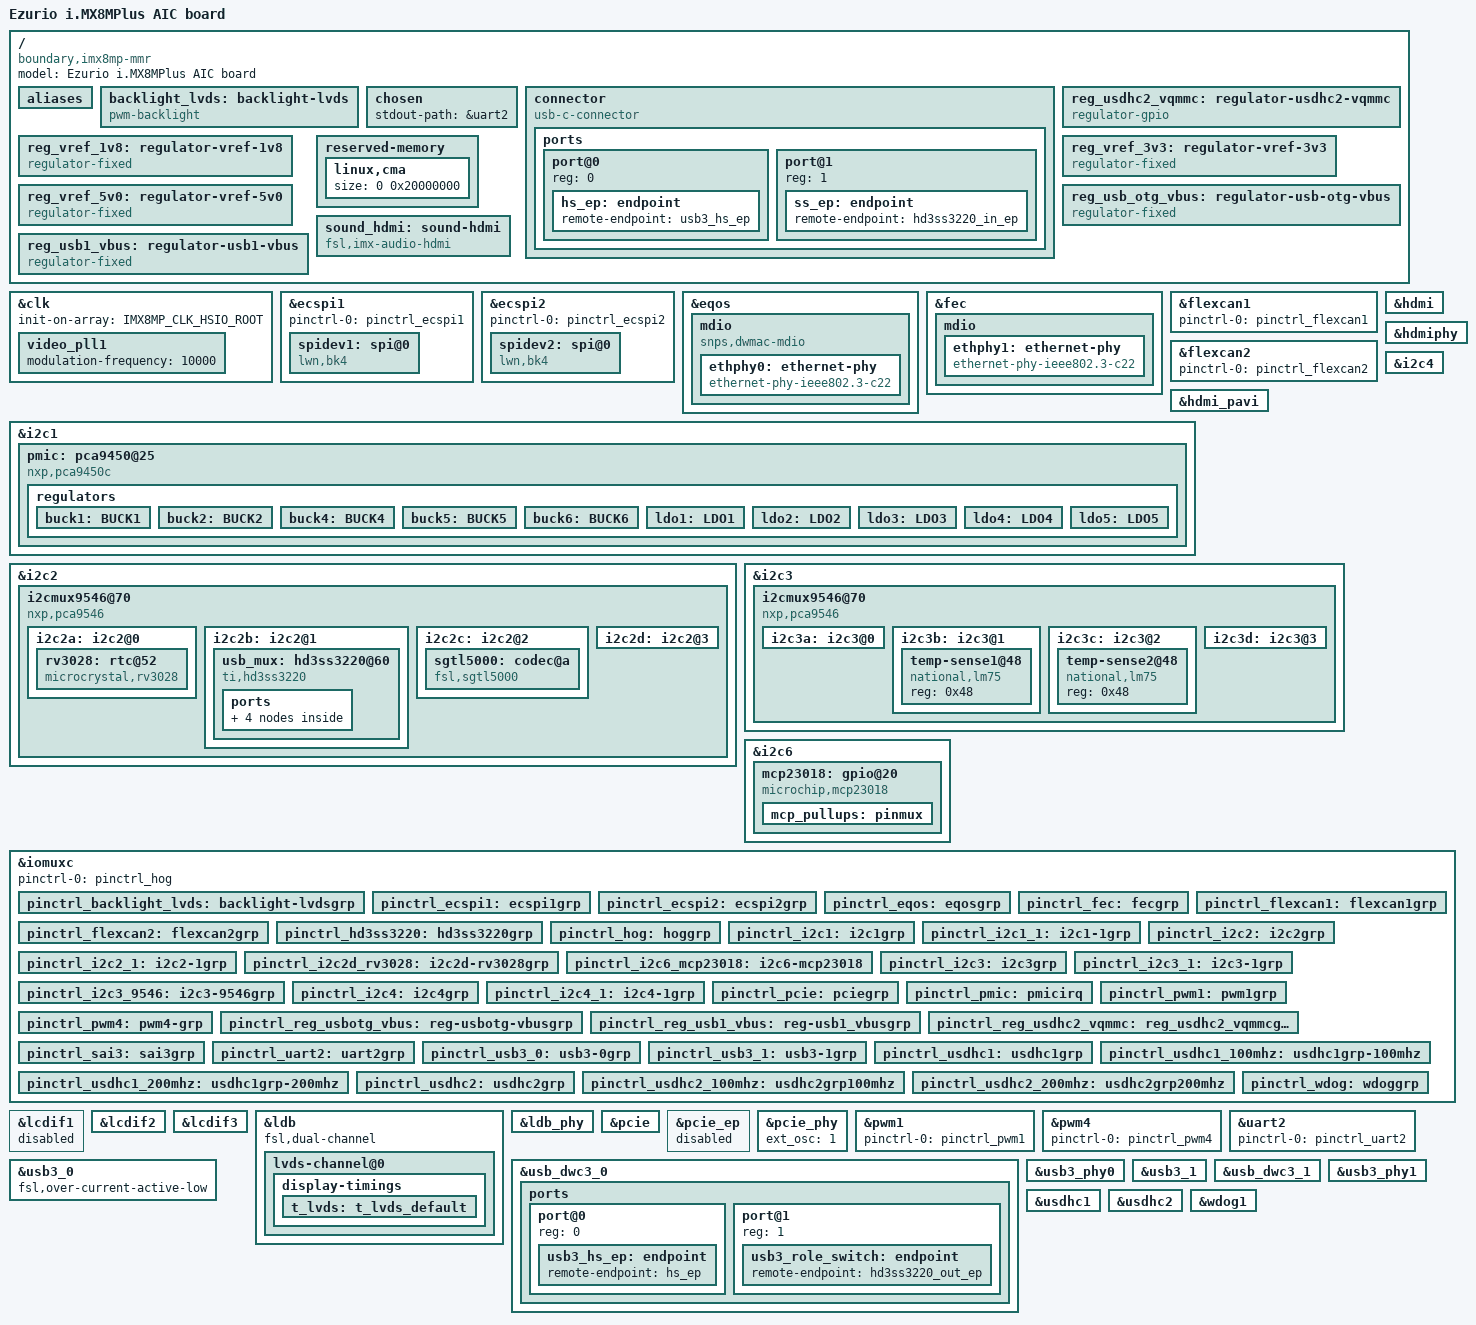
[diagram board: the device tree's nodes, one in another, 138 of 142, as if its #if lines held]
// SPDX-License-Identifier: (GPL-2.0+ OR MIT)
/*
 * Copyright 2020 Boundary Devices
 */

/dts-v1/;
#ifdef CONFIG_DEFCONFIG
#define UBOOT
#endif
#define IMX8MP

#include <dt-bindings/usb/pd.h>
#include "imx8mp.dtsi"
#include <dt-bindings/net/ti-dp83867.h>

/ {
	model = "Ezurio i.MX8MPlus AIC board";
	compatible = "boundary,imx8mp-mmr", "fsl,imx8mp";

	aliases {
		backlight_lvds = &backlight_lvds;
		ethernet0 = &eqos;
		ethernet1 = &fec;
		fb_lvds = &lcdif2;
		fb_lvds2 = &lcdif2;
		fb_hdmi = &lcdif3;
		lcdif = &lcdif1;
		ldb = &ldb;
		ldb_chan = &ldb_chan;
		ldb_chan2 = &ldb_chan2;
		pcie-phy = &pcie_phy;
		pwm_lvds = &pwm1;
		rtc0 = &rv3028;
		rtc1 = &snvs_rtc;
		sound_hdmi = &sound_hdmi;
		t_lvds = &t_lvds;
	};

	backlight_lvds: backlight-lvds {
		brightness-levels = <0 1 2 3 4 5 6 7 8 9 10>;
		compatible = "pwm-backlight";
		default-brightness-level = <8>;
		//enable-gpios = <&gpio4 3 GPIO_ACTIVE_HIGH>;
		//pinctrl-names = "default";
		//pinctrl-0 = <&pinctrl_backlight_lvds>;
		pwms = <&pwm1 0 100000 0>;
		status = "okay";
	};

	chosen {
		stdout-path = &uart2;
	};

	connector {
		compatible = "usb-c-connector";
		label = "USB-C";
		data-role = "dual";

		ports {
			#address-cells = <1>;
			#size-cells = <0>;

			port@0 {
				reg = <0>;
				hs_ep: endpoint {
					remote-endpoint = <&usb3_hs_ep>;
				};
			};

			port@1 {
				reg = <1>;
				ss_ep: endpoint {
					remote-endpoint = <&hd3ss3220_in_ep>;
				};
			};
		};
	};

	reg_usdhc2_vqmmc: regulator-usdhc2-vqmmc {
		compatible = "regulator-gpio";
		pinctrl-names = "default";
		pinctrl-0 = <&pinctrl_reg_usdhc2_vqmmc>;
		regulator-name = "reg_sd2_vsel";
		regulator-min-microvolt = <1800000>;
		regulator-max-microvolt = <3300000>;
		regulator-type = "voltage";
		regulator-boot-on;
		regulator-always-on;
		gpios = <&gpio1 4 GPIO_ACTIVE_HIGH>;
		states = <1800000 0x1
			  3300000 0x0>;
	};

	reg_vref_1v8: regulator-vref-1v8 {
		compatible = "regulator-fixed";
		regulator-name = "vref-1v8";
		regulator-min-microvolt = <1800000>;
		regulator-max-microvolt = <1800000>;
	};

	reg_vref_3v3: regulator-vref-3v3 {
		compatible = "regulator-fixed";
		regulator-name = "vref-3v3";
		regulator-min-microvolt = <3300000>;
		regulator-max-microvolt = <3300000>;
	};

	reg_vref_5v0: regulator-vref-5v0 {
		compatible = "regulator-fixed";
		regulator-name = "vref-5v0";
		regulator-min-microvolt = <5000000>;
		regulator-max-microvolt = <5000000>;
	};

	reg_usb_otg_vbus: regulator-usb-otg-vbus {
		compatible = "regulator-fixed";
		pinctrl-names = "default";
		pinctrl-0 = <&pinctrl_reg_usbotg_vbus>;
		regulator-name = "usb_otg_vbus";
		regulator-min-microvolt = <5000000>;
		regulator-max-microvolt = <5000000>;
		gpio = <&gpio1 13 GPIO_ACTIVE_HIGH>;
		enable-active-high;
	};

	reg_usb1_vbus: regulator-usb1-vbus {
		compatible = "regulator-fixed";
		pinctrl-names = "default";
		pinctrl-0 = <&pinctrl_reg_usb1_vbus>;
		regulator-name = "usb_host_vbus";
		regulator-min-microvolt = <5000000>;
		regulator-max-microvolt = <5000000>;
		gpio = <&gpio3 6 GPIO_ACTIVE_HIGH>;
		enable-active-high;
	};

	reserved-memory {
		linux,cma {
			size = <0 0x20000000>;
		};
	};

#ifndef UBOOT
	clk_pwm4: clock-pwm4 {
		compatible = "pwm-clock";
		#clock-cells = <0>;
		clock-frequency = <12000000>;
		clock-output-names = "codec-pwm4";
		pwms = <&pwm4 0 83 0>;
	};

	sound {
		compatible = "simple-audio-card";
		simple-audio-card,name = "SGTL5000-Card";
		simple-audio-card,format = "i2s";
		simple-audio-card,bitclock-master = <&codec_dai>;
		simple-audio-card,frame-master = <&codec_dai>;
		simple-audio-card,widgets = "Headphone", "Headphone Jack";
		simple-audio-card,routing = "Headphone Jack", "HP_OUT";

		cpu_dai: simple-audio-card,cpu {
			sound-dai = <&sai3>;
		};

		codec_dai: simple-audio-card,codec {
			sound-dai = <&sgtl5000>;
		};
	};
#endif
	sound_hdmi: sound-hdmi {
		compatible = "fsl,imx-audio-hdmi";
		model = "audio-hdmi";
#ifndef UBOOT
		audio-cpu = <&aud2htx>;
#endif
		hdmi-out;
		constraint-rate = <44100>,
				<88200>,
				<176400>,
				<32000>,
				<48000>,
				<96000>,
				<192000>;
		status = "okay";
	};

};

#ifndef UBOOT
&A53_0 {
	cpu-supply = <&buck2>;
};

&A53_1 {
	cpu-supply = <&buck2>;
};

&A53_2 {
	cpu-supply = <&buck2>;
};

&A53_3 {
	cpu-supply = <&buck2>;
};

&aips3 {
};

&aud2htx {
	status = "okay";
};
#endif

&clk {
	init-on-array = <IMX8MP_CLK_HSIO_ROOT>;

	video_pll1 {
		modulation-frequency = <10000>;
	};
};

#ifndef UBOOT
&easrc {
	fsl,asrc-rate  = <48000>;
	status = "okay";
};
#endif

&ecspi1 {
	pinctrl-names = "default";
	pinctrl-0 = <&pinctrl_ecspi1>;
	status = "okay";

	spidev1: spi@0 {
		compatible = "lwn,bk4";
		reg = <0>;
		spi-max-frequency = <1000000>;
	};
};

&ecspi2 {
	pinctrl-names = "default";
	pinctrl-0 = <&pinctrl_ecspi2>;
	status = "okay";

	spidev2: spi@0 {
		compatible = "lwn,bk4";
		reg = <0>;
		spi-max-frequency = <1000000>;
	};
};

&eqos {
	pinctrl-names = "default";
	pinctrl-0 = <&pinctrl_eqos>;
	phy-mode = "rgmii-id";
	phy-handle = <&ethphy0>;
	status = "okay";

	mdio {
		compatible = "snps,dwmac-mdio";
		#address-cells = <1>;
		#size-cells = <0>;

		ethphy0: ethernet-phy {
			compatible = "ethernet-phy-ieee802.3-c22";
			at803x,hib-disabled;
			eee-broken-1000t;
			interrupts-extended = <&gpio1 3 IRQ_TYPE_LEVEL_LOW>;
#if 0
			reset-gpios = <&gpio3 16 GPIO_ACTIVE_LOW>;
#endif
			reg-mask = <0x90>;
		};
	};
};

&fec {
	pinctrl-names = "default";
	pinctrl-0 = <&pinctrl_fec>;

	phy-mode = "rgmii-id";
	phy-handle = <&ethphy1>;
	fsl,magic-packet;
	status = "okay";

	mdio {
		#address-cells = <1>;
		#size-cells = <0>;

		ethphy1: ethernet-phy {
			compatible = "ethernet-phy-ieee802.3-c22";
			eee-broken-1000t;
			interrupts-extended = <&gpio1 7 IRQ_TYPE_LEVEL_LOW>;
			reg-mask = <0x90>;
		};
	};
};

&flexcan1 {
	pinctrl-names = "default";
	pinctrl-0 = <&pinctrl_flexcan1>;
};

&flexcan2 {
	pinctrl-names = "default";
	pinctrl-0 = <&pinctrl_flexcan2>;
};

#ifndef UBOOT
&gpu_2d {
	status = "okay";
};

&gpu_3d {
	status = "okay";
};
#endif

&hdmi {
	status = "okay";
};

&hdmiphy {
	status = "okay";
};

#ifndef UBOOT
&hdmi_blk_ctrl {
	status = "okay";
};
#endif

&hdmi_pavi {
	status = "okay";
};

&i2c1 {
	clock-frequency = <400000>;
	pinctrl-names = "default", "gpio";
	pinctrl-0 = <&pinctrl_i2c1>;
	pinctrl-1 = <&pinctrl_i2c1_1>;
	scl-gpios = <&gpio5 14 GPIO_OPEN_DRAIN>;
	sda-gpios = <&gpio5 15 GPIO_OPEN_DRAIN>;
	status = "okay";

	pmic: pca9450@25 {
		reg = <0x25>;
		compatible = "nxp,pca9450c";
		/* PMIC PCA9450 PMIC_nINT GPIO1_IO3 */
		pinctrl-0 = <&pinctrl_pmic>;
		interrupts-extended = <&gpio3 0 IRQ_TYPE_LEVEL_LOW>;

		regulators {
			buck1: BUCK1 {
				regulator-name = "BUCK1";
				regulator-min-microvolt = <600000>;
				regulator-max-microvolt = <2187500>;
				regulator-boot-on;
				regulator-always-on;
				regulator-ramp-delay = <3125>;
			};

			buck2: BUCK2 {
				regulator-name = "BUCK2";
				regulator-min-microvolt = <600000>;
				regulator-max-microvolt = <2187500>;
				regulator-limit-microvolt = <1025000>;
				regulator-boot-on;
				regulator-always-on;
				regulator-ramp-delay = <3125>;
				nxp,dvs-run-voltage = <950000>;
				nxp,dvs-standby-voltage = <850000>;
			};

			buck4: BUCK4 {
				regulator-name = "BUCK4";
				regulator-min-microvolt = <600000>;
				regulator-max-microvolt = <3400000>;
				regulator-boot-on;
				regulator-always-on;
			};

			buck5: BUCK5 {
				regulator-name = "BUCK5";
				regulator-min-microvolt = <600000>;
				regulator-max-microvolt = <3400000>;
				regulator-boot-on;
				regulator-always-on;
			};

			buck6: BUCK6 {
				regulator-name = "BUCK6";
				regulator-min-microvolt = <600000>;
				regulator-max-microvolt = <3400000>;
				regulator-boot-on;
				regulator-always-on;
			};

			ldo1: LDO1 {
				regulator-name = "LDO1";
				regulator-min-microvolt = <1600000>;
				regulator-max-microvolt = <3300000>;
				regulator-boot-on;
				regulator-always-on;
			};

			ldo2: LDO2 {
				regulator-name = "LDO2";
				regulator-min-microvolt = <800000>;
				regulator-max-microvolt = <1150000>;
				regulator-boot-on;
				regulator-always-on;
			};

			ldo3: LDO3 {
				regulator-name = "LDO3";
				regulator-min-microvolt = <800000>;
				regulator-max-microvolt = <3300000>;
				regulator-boot-on;
				regulator-always-on;
			};

			ldo4: LDO4 {
				regulator-name = "LDO4";
				regulator-min-microvolt = <800000>;
				regulator-max-microvolt = <3300000>;
				regulator-boot-on;
				regulator-always-on;
			};

			ldo5: LDO5 {
				regulator-name = "LDO5";
				regulator-min-microvolt = <1800000>;
				regulator-max-microvolt = <3300000>;
				regulator-boot-on;
				regulator-always-on;
			};
		};
	};
};

&i2c2 { /* GP */
	clock-frequency = <100000>;
	pinctrl-names = "default", "gpio";
	pinctrl-0 = <&pinctrl_i2c2>;
	pinctrl-1 = <&pinctrl_i2c2_1>;
	scl-gpios = <&gpio5 16 GPIO_OPEN_DRAIN>;
	sda-gpios = <&gpio5 17 GPIO_OPEN_DRAIN>;
	status = "okay";

	i2cmux9546@70 {
		compatible = "nxp,pca9546";
		reg = <0x70>;
		reset-gpios = <&mcp23018 6 GPIO_ACTIVE_LOW>;
		#address-cells = <1>;
		#size-cells = <0>;

		i2c2a: i2c2@0 {
			/* RTC I2C*/
			clock-frequency = <100000>;
			reg = <0>;
			#address-cells = <1>;
			#size-cells = <0>;

			rv3028: rtc@52 {
				compatible = "microcrystal,rv3028";
				reg = <0x52>;
				trickle-resistor-ohms = <3000>;
				pinctrl-names = "default";
				pinctrl-0 = <&pinctrl_i2c2d_rv3028>;
				interrupts-extended = <&gpio1 1 IRQ_TYPE_LEVEL_LOW>;
			};
		};

		i2c2b: i2c2@1 {
			/*  USB-C I2C*/
			clock-frequency = <100000>;
			reg = <0>;
			#address-cells = <1>;
			#size-cells = <0>;

			usb_mux: hd3ss3220@60 {
				compatible = "ti,hd3ss3220";
				interrupts-extended = <&gpio4 18 IRQ_TYPE_LEVEL_LOW>;
				pinctrl-names = "default";
				pinctrl-0 = <&pinctrl_hd3ss3220>;
				reg = <0x60>;

				ports {
					#address-cells = <1>;
					#size-cells = <0>;

					port@0 {
						reg = <0>;
						hd3ss3220_in_ep: endpoint {
							remote-endpoint = <&ss_ep>;
						};
					};

					port@1 {
						reg = <1>;
						hd3ss3220_out_ep: endpoint {
							remote-endpoint = <&usb3_role_switch>;
						};
					};
				};
			};
		};

		i2c2c: i2c2@2 {
			/* AUDIO I2C*/
			clock-frequency = <100000>;
			reg = <0>;
			#address-cells = <1>;
			#size-cells = <0>;

			sgtl5000: codec@a {
				compatible = "fsl,sgtl5000";
				reg = <0x0a>;
				#sound-dai-cells = <0>;
				clocks = <&clk_pwm4>;
				VDDA-supply = <&reg_vref_3v3>;
				VDDIO-supply = <&reg_vref_3v3>;
			};
		};

		i2c2d: i2c2@3 {
			/* ADV7611 I2C*/
			clock-frequency = <100000>;
			reg = <0>;
			#address-cells = <1>;
			#size-cells = <0>;
		};

	};
};

/* I2C_LCD */
&i2c3 {
	clock-frequency = <100000>;
	pinctrl-names = "default", "gpio";
	pinctrl-0 = <&pinctrl_i2c3>;
	pinctrl-1 = <&pinctrl_i2c3_1>;
	scl-gpios = <&gpio5 18 GPIO_OPEN_DRAIN>;
	sda-gpios = <&gpio5 19 GPIO_OPEN_DRAIN>;
	status = "okay";

	i2cmux9546@70 {
		compatible = "nxp,pca9546";
		pinctrl-names = "default";
		pinctrl-0 = <&pinctrl_i2c3_9546>;
		reg = <0x70>;
		reset-gpios = <&gpio4 23 GPIO_ACTIVE_LOW>;
		#address-cells = <1>;
		#size-cells = <0>;


		i2c3a: i2c3@0 {
			/* VGA I2C*/
			clock-frequency = <100000>;
			reg = <0>;
			#address-cells = <1>;
			#size-cells = <0>;
		};

		i2c3b: i2c3@1 {
			/* TMP1 I2C*/
			clock-frequency = <100000>;
			reg = <0>;
			#address-cells = <1>;
			#size-cells = <0>;

			temp-sense1@48 {
				compatible = "national,lm75";
				reg = <0x48>;
			};
		};

		i2c3c: i2c3@2 {
			/* TMP2 I2C*/
			clock-frequency = <100000>;
			reg = <0>;
			#address-cells = <1>;
			#size-cells = <0>;

			temp-sense2@48 {
				compatible = "national,lm75";
				reg = <0x48>;
			};
		};

		i2c3d: i2c3@3 {
			/* EEP I2C*/
			clock-frequency = <100000>;
			reg = <0>;
			#address-cells = <1>;
			#size-cells = <0>;
		};
	};
};

/* I2C_PM */
&i2c4 {
	clock-frequency = <100000>;
	pinctrl-names = "default", "gpio";
	pinctrl-0 = <&pinctrl_i2c4>;
	pinctrl-1 = <&pinctrl_i2c4_1>;
	scl-gpios = <&gpio5 20 GPIO_OPEN_DRAIN>;
	sda-gpios = <&gpio5 21 GPIO_OPEN_DRAIN>;
	status = "okay";
};

&i2c6 {
	mcp23018: gpio@20 {
		compatible = "microchip,mcp23018";
		gpio-controller;
		#gpio-cells = <0x2>;
		interrupts-extended = <&gpio4 22 IRQ_TYPE_LEVEL_LOW>;
		interrupt-controller;
		#interrupt-cells = <0x2>;
		microchip,irq-mirror;
		pinctrl-names = "default";
		pinctrl-0 = <&pinctrl_i2c6_mcp23018>, <&mcp_pullups>;
		reg = <0x20>;
		reset-gpios = <&gpio4 27 GPIO_ACTIVE_LOW>;

		mcp_pullups: pinmux {
			/* gpio1 & gpio4 have external pullup */
			pins =  "gpio0", "gpio2", "gpio3",
				"gpio5", "gpio6", "gpio7",
				"gpio8", "gpio9", "gpio10", "gpio11",
				"gpio12", "gpio13", "gpio14", "gpio15";
			bias-pull-up;
		};
	};
};

&iomuxc {
	pinctrl-names = "default";
	pinctrl-0 = <&pinctrl_hog>;

	pinctrl_backlight_lvds: backlight-lvdsgrp {
		fsl,pins = <
			MX8MP_IOMUXC_SAI1_RXD1__GPIO4_IO03		0x106 /* DISP0_GPIO */
		>;
	};

	pinctrl_ecspi1: ecspi1grp {
		fsl,pins = <
			MX8MP_IOMUXC_ECSPI1_SCLK__ECSPI1_SCLK		0x82
			MX8MP_IOMUXC_ECSPI1_MOSI__ECSPI1_MOSI		0x82
			MX8MP_IOMUXC_ECSPI1_MISO__ECSPI1_MISO		0x82
			MX8MP_IOMUXC_ECSPI1_SS0__ECSPI1_SS0		0x140
		>;
	};

	pinctrl_ecspi2: ecspi2grp {
		fsl,pins = <
			MX8MP_IOMUXC_ECSPI2_SCLK__ECSPI2_SCLK		0x82
			MX8MP_IOMUXC_ECSPI2_MOSI__ECSPI2_MOSI		0x82
			MX8MP_IOMUXC_ECSPI2_MISO__ECSPI2_MISO		0x82
			MX8MP_IOMUXC_ECSPI2_SS0__ECSPI2_SS0		0x140
		>;
	};

	pinctrl_eqos: eqosgrp {
		fsl,pins = <
			MX8MP_IOMUXC_ENET_MDC__ENET_QOS_MDC		0x110
			MX8MP_IOMUXC_ENET_MDIO__ENET_QOS_MDIO		0xa0
			MX8MP_IOMUXC_ENET_TX_CTL__ENET_QOS_RGMII_TX_CTL	0x1f
			MX8MP_IOMUXC_ENET_TXC__CCM_ENET_QOS_CLOCK_GENERATE_TX_CLK	0x1f
			MX8MP_IOMUXC_ENET_TD0__ENET_QOS_RGMII_TD0		0x1f
			MX8MP_IOMUXC_ENET_TD1__ENET_QOS_RGMII_TD1		0x1f
			MX8MP_IOMUXC_ENET_TD2__ENET_QOS_RGMII_TD2		0x1f
			MX8MP_IOMUXC_ENET_TD3__ENET_QOS_RGMII_TD3		0x1f

			MX8MP_IOMUXC_ENET_RX_CTL__ENET_QOS_RGMII_RX_CTL	0x91
			MX8MP_IOMUXC_ENET_RXC__CCM_ENET_QOS_CLOCK_GENERATE_RX_CLK	0x91
			MX8MP_IOMUXC_ENET_RD0__ENET_QOS_RGMII_RD0	0x91
			MX8MP_IOMUXC_ENET_RD1__ENET_QOS_RGMII_RD1	0x91
			MX8MP_IOMUXC_ENET_RD2__ENET_QOS_RGMII_RD2	0x91
			MX8MP_IOMUXC_ENET_RD3__ENET_QOS_RGMII_RD3	0x91
			MX8MP_IOMUXC_NAND_READY_B__GPIO3_IO16		0x100
			MX8MP_IOMUXC_GPIO1_IO03__GPIO1_IO03             0x140
		>;
	};

	pinctrl_fec: fecgrp {
		fsl,pins = <
			MX8MP_IOMUXC_SAI1_RXD2__ENET1_MDC		0x0
			MX8MP_IOMUXC_SAI1_RXD3__ENET1_MDIO	0xa0
			MX8MP_IOMUXC_SAI1_TXD4__ENET1_RGMII_TX_CTL	0x1f
			MX8MP_IOMUXC_SAI1_TXD5__ENET1_RGMII_TXC	0x1f
			MX8MP_IOMUXC_SAI1_TXD0__ENET1_RGMII_TD0	0x1f
			MX8MP_IOMUXC_SAI1_TXD1__ENET1_RGMII_TD1	0x1f
			MX8MP_IOMUXC_SAI1_TXD2__ENET1_RGMII_TD2	0x1f
			MX8MP_IOMUXC_SAI1_TXD3__ENET1_RGMII_TD3	0x1f

			MX8MP_IOMUXC_SAI1_TXFS__ENET1_RGMII_RX_CTL	0x91
			MX8MP_IOMUXC_SAI1_TXC__ENET1_RGMII_RXC	0x91
			MX8MP_IOMUXC_SAI1_RXD4__ENET1_RGMII_RD0	0x91
			MX8MP_IOMUXC_SAI1_RXD5__ENET1_RGMII_RD1	0x91
			MX8MP_IOMUXC_SAI1_RXD6__ENET1_RGMII_RD2	0x91
			MX8MP_IOMUXC_SAI1_RXD7__ENET1_RGMII_RD3	0x91
#define GP_FEC_RESET	<&gpio1 12 GPIO_ACTIVE_LOW>
			MX8MP_IOMUXC_GPIO1_IO12__GPIO1_IO12	0x100
#define GPIRQ_FEC_PHY	<&gpio1 7 IRQ_TYPE_LEVEL_LOW>
			MX8MP_IOMUXC_GPIO1_IO07__GPIO1_IO07	0x1c0
		>;
	};

	pinctrl_flexcan1: flexcan1grp {
		fsl,pins = <
			MX8MP_IOMUXC_SAI5_RXD2__CAN1_RX			0x154
			MX8MP_IOMUXC_SAI5_RXD1__CAN1_TX			0x154
		>;
	};

	pinctrl_flexcan2: flexcan2grp {
		fsl,pins = <
			MX8MP_IOMUXC_SAI5_MCLK__CAN2_RX			0x154
			MX8MP_IOMUXC_SAI5_RXD3__CAN2_TX			0x154
		>;
	};

	pinctrl_hd3ss3220: hd3ss3220grp {
		fsl,pins = <
			MX8MP_IOMUXC_SAI1_TXD6__GPIO4_IO18	0x1c0
		>;
	};

	pinctrl_hog: hoggrp {
		fsl,pins = <
			MX8MP_IOMUXC_HDMI_DDC_SCL__HDMIMIX_HDMI_SCL	0x400001c3
			MX8MP_IOMUXC_HDMI_DDC_SDA__HDMIMIX_HDMI_SDA	0x400001c3
			MX8MP_IOMUXC_HDMI_HPD__HDMIMIX_HDMI_HPD		0x40000019
			MX8MP_IOMUXC_HDMI_CEC__HDMIMIX_HDMI_CEC		0x40000019
		>;
	};

	pinctrl_i2c1: i2c1grp {
		fsl,pins = <
			MX8MP_IOMUXC_I2C1_SCL__I2C1_SCL		0x400001c3
			MX8MP_IOMUXC_I2C1_SDA__I2C1_SDA		0x400001c3
		>;
	};

	pinctrl_i2c1_1: i2c1-1grp {
		fsl,pins = <
			MX8MP_IOMUXC_I2C1_SCL__GPIO5_IO14	0x1c3
			MX8MP_IOMUXC_I2C1_SDA__GPIO5_IO15	0x1c3
		>;
	};

	pinctrl_i2c2: i2c2grp {
		fsl,pins = <
			MX8MP_IOMUXC_I2C2_SCL__I2C2_SCL		0x400001c3
			MX8MP_IOMUXC_I2C2_SDA__I2C2_SDA		0x400001c3
		>;
	};

	pinctrl_i2c2_1: i2c2-1grp {
		fsl,pins = <
			MX8MP_IOMUXC_I2C2_SCL__GPIO5_IO16	0x1c3
			MX8MP_IOMUXC_I2C2_SDA__GPIO5_IO17	0x1c3
		>;
	};

	pinctrl_i2c2d_rv3028: i2c2d-rv3028grp {
		fsl,pins = <
			MX8MP_IOMUXC_GPIO1_IO01__GPIO1_IO01	0x100
		>;
	};

	pinctrl_i2c6_mcp23018: i2c6-mcp23018 {
		fsl,pins = <
			MX8MP_IOMUXC_SAI2_RXC__GPIO4_IO22	0x100
			MX8MP_IOMUXC_SAI2_MCLK__GPIO4_IO27	0x100
		>;
	};

	pinctrl_i2c3: i2c3grp {
		fsl,pins = <
			MX8MP_IOMUXC_I2C3_SCL__I2C3_SCL		0x400001c3
			MX8MP_IOMUXC_I2C3_SDA__I2C3_SDA		0x400001c3
		>;
	};

	pinctrl_i2c3_1: i2c3-1grp {
		fsl,pins = <
			MX8MP_IOMUXC_I2C3_SCL__GPIO5_IO18       0x1c3
			MX8MP_IOMUXC_I2C3_SDA__GPIO5_IO19       0x1c3
		>;
	};

	pinctrl_i2c3_9546: i2c3-9546grp {
		fsl,pins = <
			MX8MP_IOMUXC_SAI2_RXD0__GPIO4_IO23	0x100
		>;
	};

	pinctrl_i2c4: i2c4grp {
		fsl,pins = <
			MX8MP_IOMUXC_I2C4_SCL__I2C4_SCL		0x400001c3
			MX8MP_IOMUXC_I2C4_SDA__I2C4_SDA		0x400001c3
		>;
	};

	pinctrl_i2c4_1: i2c4-1grp {
		fsl,pins = <
			MX8MP_IOMUXC_I2C4_SCL__GPIO5_IO20       0x1c3
			MX8MP_IOMUXC_I2C4_SDA__GPIO5_IO21       0x1c3
		>;
	};

	pinctrl_pcie: pciegrp {
		fsl,pins = <
			MX8MP_IOMUXC_SAI1_RXFS__GPIO4_IO00	0x1c0
			MX8MP_IOMUXC_SAI2_RXFS__GPIO4_IO21	0x1c0
			MX8MP_IOMUXC_SAI3_RXFS__GPIO4_IO28	0x1c0
		>;
	};

	pinctrl_pmic: pmicirq {
		fsl,pins = <
			MX8MP_IOMUXC_NAND_ALE__GPIO3_IO00	0x41
		>;
	};

	pinctrl_pwm1: pwm1grp {
		fsl,pins = <
			MX8MP_IOMUXC_GPIO1_IO08__PWM1_OUT	0x160  /* SimonG see that we patched this and added a transistor*/
		>;
	};

	pinctrl_pwm4: pwm4-grp {
		fsl,pins = <
			MX8MP_IOMUXC_SAI3_MCLK__PWM4_OUT	0xd6
		>;
	};

	pinctrl_reg_usbotg_vbus: reg-usbotg-vbusgrp {
		fsl,pins = <
			MX8MP_IOMUXC_GPIO1_IO13__GPIO1_IO13	0x100
		>;
	};

	pinctrl_reg_usb1_vbus: reg-usb1_vbusgrp {
		fsl,pins = <
			MX8MP_IOMUXC_NAND_DATA00__GPIO3_IO06	0x100
		>;
	};

	pinctrl_reg_usdhc2_vqmmc: reg_usdhc2_vqmmcgrp {
		fsl,pins = <
			MX8MP_IOMUXC_GPIO1_IO04__GPIO1_IO04	0x116
		>;
	};

	pinctrl_sai3: sai3grp {
		fsl,pins = <
			/* I2S0 */
			MX8MP_IOMUXC_SAI3_TXFS__AUDIOMIX_SAI3_TX_SYNC	0xd6
			MX8MP_IOMUXC_SAI3_TXC__AUDIOMIX_SAI3_TX_BCLK	0xd6
			MX8MP_IOMUXC_SAI3_RXD__AUDIOMIX_SAI3_RX_DATA00	0xd6
			MX8MP_IOMUXC_SAI3_TXD__AUDIOMIX_SAI3_TX_DATA00	0xd6
			MX8MP_IOMUXC_SAI3_MCLK__AUDIOMIX_SAI3_MCLK	0xd6
			/* Mic Detect */
			MX8MP_IOMUXC_SAI1_MCLK__GPIO4_IO20		0x143
			/* AUD_STBY*/
			MX8MP_IOMUXC_SD2_WP__USDHC2_WP			0x1d0a
		>;
	};

	pinctrl_uart2: uart2grp {
		fsl,pins = <
			MX8MP_IOMUXC_UART2_RXD__UART2_DCE_RX	0x140
			MX8MP_IOMUXC_UART2_TXD__UART2_DCE_TX	0x140
		>;
	};

	pinctrl_usb3_0: usb3-0grp {
		fsl,pins = <
			//MX8MP_IOMUXC_GPIO1_IO13__USB1_OC	0x1c0
			MX8MP_IOMUXC_GPIO1_IO13__USB1_OTG_OC	0x1c0
		>;
	};

	pinctrl_usb3_1: usb3-1grp {
		fsl,pins = <
			MX8MP_IOMUXC_NAND_DATA00__GPIO3_IO06    0x100
		>;
	};

	pinctrl_usdhc1: usdhc1grp {
		fsl,pins = <
			MX8MP_IOMUXC_SD1_CLK__USDHC1_CLK	0x10
			MX8MP_IOMUXC_SD1_CMD__USDHC1_CMD	0x150
			MX8MP_IOMUXC_SD1_DATA0__USDHC1_DATA0	0x150
			MX8MP_IOMUXC_SD1_DATA1__USDHC1_DATA1	0x150
			MX8MP_IOMUXC_SD1_DATA2__USDHC1_DATA2	0x150
			MX8MP_IOMUXC_SD1_DATA3__USDHC1_DATA3	0x150
			MX8MP_IOMUXC_SD1_DATA4__USDHC1_DATA4	0x150
			MX8MP_IOMUXC_SD1_DATA5__USDHC1_DATA5	0x150
			MX8MP_IOMUXC_SD1_DATA6__USDHC1_DATA6	0x150
			MX8MP_IOMUXC_SD1_DATA7__USDHC1_DATA7	0x150
			MX8MP_IOMUXC_SD1_STROBE__USDHC1_STROBE	0x10
			MX8MP_IOMUXC_SD1_RESET_B__USDHC1_RESET_B 0x140
		>;
	};

	pinctrl_usdhc1_100mhz: usdhc1grp-100mhz {
		fsl,pins = <
			MX8MP_IOMUXC_SD1_CLK__USDHC1_CLK	0x14
			MX8MP_IOMUXC_SD1_CMD__USDHC1_CMD	0x154
			MX8MP_IOMUXC_SD1_DATA0__USDHC1_DATA0	0x154
			MX8MP_IOMUXC_SD1_DATA1__USDHC1_DATA1	0x154
			MX8MP_IOMUXC_SD1_DATA2__USDHC1_DATA2	0x154
			MX8MP_IOMUXC_SD1_DATA3__USDHC1_DATA3	0x154
			MX8MP_IOMUXC_SD1_DATA4__USDHC1_DATA4	0x154
			MX8MP_IOMUXC_SD1_DATA5__USDHC1_DATA5	0x154
			MX8MP_IOMUXC_SD1_DATA6__USDHC1_DATA6	0x154
			MX8MP_IOMUXC_SD1_DATA7__USDHC1_DATA7	0x154
			MX8MP_IOMUXC_SD1_STROBE__USDHC1_STROBE	0x14
		>;
	};

	pinctrl_usdhc1_200mhz: usdhc1grp-200mhz {
		fsl,pins = <
			MX8MP_IOMUXC_SD1_CLK__USDHC1_CLK	0x12
			MX8MP_IOMUXC_SD1_CMD__USDHC1_CMD	0x152
			MX8MP_IOMUXC_SD1_DATA0__USDHC1_DATA0	0x152
			MX8MP_IOMUXC_SD1_DATA1__USDHC1_DATA1	0x152
			MX8MP_IOMUXC_SD1_DATA2__USDHC1_DATA2	0x152
			MX8MP_IOMUXC_SD1_DATA3__USDHC1_DATA3	0x152
			MX8MP_IOMUXC_SD1_DATA4__USDHC1_DATA4	0x152
			MX8MP_IOMUXC_SD1_DATA5__USDHC1_DATA5	0x152
			MX8MP_IOMUXC_SD1_DATA6__USDHC1_DATA6	0x152
			MX8MP_IOMUXC_SD1_DATA7__USDHC1_DATA7	0x152
			MX8MP_IOMUXC_SD1_STROBE__USDHC1_STROBE	0x12
		>;
	};

	pinctrl_usdhc2: usdhc2grp {
		fsl,pins = <
			MX8MP_IOMUXC_SD2_CLK__USDHC2_CLK	0x190
			MX8MP_IOMUXC_SD2_CMD__USDHC2_CMD	0x1d0
			MX8MP_IOMUXC_SD2_DATA0__USDHC2_DATA0	0x1d0
			MX8MP_IOMUXC_SD2_DATA1__USDHC2_DATA1	0x1d0
			MX8MP_IOMUXC_SD2_DATA2__USDHC2_DATA2	0x1d0
			MX8MP_IOMUXC_SD2_DATA3__USDHC2_DATA3	0x1d0
			MX8MP_IOMUXC_SD2_CD_B__GPIO2_IO12	0x1d0
		>;
	};

	pinctrl_usdhc2_100mhz: usdhc2grp100mhz {
		fsl,pins = <
			MX8MP_IOMUXC_SD2_CLK__USDHC2_CLK	0x194
			MX8MP_IOMUXC_SD2_CMD__USDHC2_CMD	0x1d4
			MX8MP_IOMUXC_SD2_DATA0__USDHC2_DATA0	0x1d4
			MX8MP_IOMUXC_SD2_DATA1__USDHC2_DATA1	0x1d4
			MX8MP_IOMUXC_SD2_DATA2__USDHC2_DATA2	0x1d4
			MX8MP_IOMUXC_SD2_DATA3__USDHC2_DATA3	0x1d4
		>;
	};

	pinctrl_usdhc2_200mhz: usdhc2grp200mhz {
		fsl,pins = <
			MX8MP_IOMUXC_SD2_CLK__USDHC2_CLK	0x196
			MX8MP_IOMUXC_SD2_CMD__USDHC2_CMD	0x1d6
			MX8MP_IOMUXC_SD2_DATA0__USDHC2_DATA0	0x1d6
			MX8MP_IOMUXC_SD2_DATA1__USDHC2_DATA1	0x1d6
			MX8MP_IOMUXC_SD2_DATA2__USDHC2_DATA2	0x1d6
			MX8MP_IOMUXC_SD2_DATA3__USDHC2_DATA3	0x1d6
		>;
	};

	pinctrl_wdog: wdoggrp {
		fsl,pins = <
			MX8MP_IOMUXC_GPIO1_IO02__WDOG1_WDOG_B	0xc6
		>;
	};
};

#ifndef UBOOT
&irqsteer_hdmi {
	status = "okay";
};
#endif

&lcdif1 {
	status = "disabled";
};

&lcdif2 {
	status = "okay";
};

&lcdif3 {
	status = "okay";
};

&ldb {
	status = "okay";
	fsl,dual-channel;
	lvds-channel@0 {
		status = "okay";
		backlight = <&backlight_lvds>;
		fsl,data-mapping = "spwg";
		fsl,data-width = <24>;

		display-timings {
			t_lvds: t_lvds_default {
				/* AUO  by default */
				clock-frequency = <74250000>;
				hactive = <1920>;
				vactive = <1080>;
				hback-porch = <182>;
				hfront-porch = <90>;
				vback-porch = <24>;
				vfront-porch = <18>;
				hsync-len = <8>;
				vsync-len = <3>;
#if 0
				/* Innolux g156hce */
				clock-frequency = <141860000>;
				hactive = <1920>;
				vactive = <1080>;
				hback-porch = <90>;
				hfront-porch = <90>;
				vback-porch = <10>;
				vfront-porch = <10>;
				hsync-len = <30>;
				vsync-len = <10>;
				de-active = <1>;
#endif
			};
		};
	};
};

&ldb_phy {
	status = "okay";
};

#ifndef UBOOT
&mix_gpu_ml {
	status = "okay";
};

&ml_vipsi {
	status = "okay";
};
#endif

&pcie{
	pinctrl-names = "default";
	pinctrl-0 = <&pinctrl_pcie>;
	//disable-gpio = <&gpio2 6 GPIO_ACTIVE_LOW>;
	reset-gpio = <&gpio4 21 GPIO_ACTIVE_LOW>;
	ext_osc = <1>;
	clocks = <&clk IMX8MP_CLK_HSIO_ROOT>,
		 <&clk IMX8MP_CLK_PCIE_AUX>,
		 <&clk IMX8MP_CLK_HSIO_AXI>,
		 <&clk IMX8MP_CLK_PCIE_ROOT>;
	clock-names = "pcie", "pcie_aux", "pcie_phy", "pcie_bus";
	assigned-clocks = <&clk IMX8MP_CLK_HSIO_AXI>,
			  <&clk IMX8MP_CLK_PCIE_AUX>;
	assigned-clock-rates = <500000000>, <10000000>;
	assigned-clock-parents = <&clk IMX8MP_SYS_PLL2_500M>,
				 <&clk IMX8MP_SYS_PLL2_50M>;
	l1ss-disabled;
	status = "okay";
};

&pcie_ep{
	pinctrl-names = "default";
	pinctrl-0 = <&pinctrl_pcie>;
	ext_osc = <1>;
	clocks = <&clk IMX8MP_CLK_HSIO_ROOT>,
		 <&clk IMX8MP_CLK_PCIE_AUX>,
		 <&clk IMX8MP_CLK_HSIO_AXI>,
		 <&clk IMX8MP_CLK_PCIE_ROOT>;
	clock-names = "pcie", "pcie_aux", "pcie_phy", "pcie_bus";
	assigned-clocks = <&clk IMX8MP_CLK_HSIO_AXI>,
			  <&clk IMX8MP_CLK_PCIE_AUX>;
	assigned-clock-rates = <500000000>, <10000000>;
	assigned-clock-parents = <&clk IMX8MP_SYS_PLL2_500M>,
				 <&clk IMX8MP_SYS_PLL2_50M>;
	status = "disabled";
};

&pcie_phy{
	ext_osc = <1>;
	status = "okay";
};

&pwm1 {
	pinctrl-names = "default";
	pinctrl-0 = <&pinctrl_pwm1>;
	status = "okay";
};

&pwm4 {
	pinctrl-names = "default";
	pinctrl-0 = <&pinctrl_pwm4>;
	status = "okay";
};

#ifndef UBOOT
&sai3 {
	#sound-dai-cells = <0>;
	pinctrl-names = "default";
	pinctrl-0 = <&pinctrl_sai3>;
	assigned-clocks = <&clk IMX8MP_CLK_SAI3>;
	assigned-clock-parents = <&clk IMX8MP_AUDIO_PLL1_OUT>;
	assigned-clock-rates = <12288000>;
	clocks = <&audio_blk_ctrl IMX8MP_CLK_AUDIO_BLK_CTRL_SAI3_IPG>, <&clk IMX8MP_CLK_DUMMY>,
		 <&audio_blk_ctrl IMX8MP_CLK_AUDIO_BLK_CTRL_SAI3_MCLK1>, <&clk IMX8MP_CLK_DUMMY>,
		 <&clk IMX8MP_CLK_DUMMY>;
	clock-names = "bus", "mclk0", "mclk1", "mclk2", "mclk3";
	fsl,sai-mclk-direction-output;
	status = "okay";
};

&sdma2 {
	status = "okay";
};

&snvs_pwrkey {
	status = "okay";
};
#endif

&uart2 {
	/* J1 - console */
	pinctrl-names = "default";
	pinctrl-0 = <&pinctrl_uart2>;
	status = "okay";
};

&usb3_0 {
	fsl,over-current-active-low;
	status = "okay";
};

&usb_dwc3_0 {
#ifdef UBOOT
	dr_mode = "otg";
#else
	dr_mode = "host";
#endif
	pinctrl-names = "default";
	pinctrl-0 = <&pinctrl_usb3_0>;
	status = "okay";
	usb-role-switch;

	ports {
		#address-cells = <1>;
		#size-cells = <0>;

		port@0 {
			reg = <0>;
			usb3_hs_ep: endpoint {
				remote-endpoint = <&hs_ep>;
			};
		};

		port@1 {
			reg = <1>;
			usb3_role_switch: endpoint {
				remote-endpoint = <&hd3ss3220_out_ep>;
			};
		};
	};
};

&usb3_phy0 {
	fsl,phy-tx-preemp-amp-tune = <2>;
	status = "okay";
	vbus-supply = <&reg_usb_otg_vbus>;
};

&usb3_1 {
	status = "okay";
};

&usb_dwc3_1 {
	dr_mode = "host";
	pinctrl-names = "default";
	pinctrl-0 = <&pinctrl_usb3_1>;
	reset-gpios = <&gpio3 6 GPIO_ACTIVE_LOW>;
	status = "okay";
};

&usb3_phy1 {
	fsl,phy-tx-preemp-amp-tune = <2>;
	status = "okay";
	vbus-supply = <&reg_usb1_vbus>;
};

&usdhc1 {
	bus-width = <8>;
	mmc-hs400-1_8v;
	mmc-hs400-enhanced-strobe;
	no-sd;
	no-sdio;
	non-removable;
	pinctrl-names = "default", "state_100mhz", "state_200mhz";
	pinctrl-0 = <&pinctrl_usdhc1>;
	pinctrl-1 = <&pinctrl_usdhc1_100mhz>;
	pinctrl-2 = <&pinctrl_usdhc1_200mhz>;
	status = "okay";
	vmmc-supply = <&reg_vref_3v3>;
	vqmmc-1-8-v;
	vqmmc-supply = <&reg_vref_1v8>;
};

&usdhc2 {
	bus-width = <4>;
	cd-gpios = <&gpio2 12 GPIO_ACTIVE_LOW>;
	fsl,wp-controller;
	pinctrl-names = "default", "state_100mhz", "state_200mhz";
	pinctrl-0 = <&pinctrl_usdhc2>;
	pinctrl-1 = <&pinctrl_usdhc2_100mhz>;
	pinctrl-2 = <&pinctrl_usdhc2_200mhz>;
	status = "okay";
	vmmc-supply = <&reg_vref_3v3>;
	vqmmc-supply = <&reg_usdhc2_vqmmc>;
};

#ifndef UBOOT
&vpu_g1 {
	status = "okay";
};

&vpu_g2 {
	status = "okay";
};

&vpu_vc8000e {
	status = "okay";
};

&vpu_v4l2 {
	status = "okay";
};
#endif

&wdog1 {
	pinctrl-names = "default";
	pinctrl-0 = <&pinctrl_wdog>;
	fsl,ext-reset-output;
	status = "okay";
};

